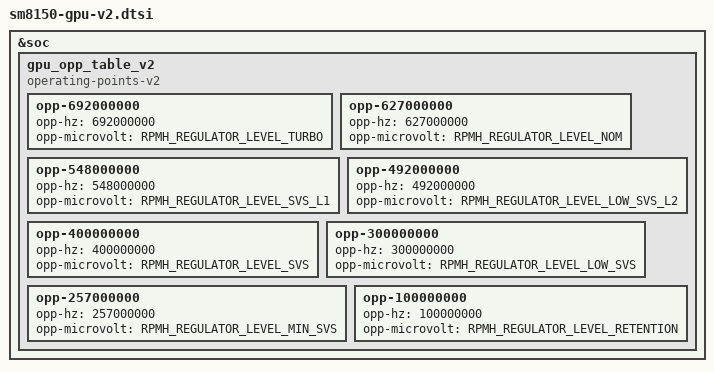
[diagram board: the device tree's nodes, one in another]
/* Copyright (c) 2018-2019, The Linux Foundation. All rights reserved.
 *
 * This program is free software; you can redistribute it and/or modify
 * it under the terms of the GNU General Public License version 2 and
 * only version 2 as published by the Free Software Foundation.
 *
 * This program is distributed in the hope that it will be useful,
 * but WITHOUT ANY WARRANTY; without even the implied warranty of
 * MERCHANTABILITY or FITNESS FOR A PARTICULAR PURPOSE.  See the
 * GNU General Public License for more details.
 */

&soc {
	gpu_opp_table_v2: gpu_opp_table_v2 {
		compatible = "operating-points-v2";

		opp-692000000 {
			opp-hz = /bits/ 64 <692000000>;
			opp-microvolt = <RPMH_REGULATOR_LEVEL_TURBO>;
		};

		opp-627000000 {
			opp-hz = /bits/ 64 <627000000>;
			opp-microvolt = <RPMH_REGULATOR_LEVEL_NOM>;
		};

		opp-548000000 {
			opp-hz = /bits/ 64 <548000000>;
			opp-microvolt = <RPMH_REGULATOR_LEVEL_SVS_L1>;
		};

		opp-492000000 {
			opp-hz = /bits/ 64 <492000000>;
			opp-microvolt = <RPMH_REGULATOR_LEVEL_LOW_SVS_L2>;
		};

		opp-400000000 {
			opp-hz = /bits/ 64 <400000000>;
			opp-microvolt = <RPMH_REGULATOR_LEVEL_SVS>;
		};

		opp-300000000 {
			opp-hz = /bits/ 64 <300000000>;
			opp-microvolt = <RPMH_REGULATOR_LEVEL_LOW_SVS>;
		};

		opp-257000000 {
			opp-hz = /bits/ 64 <257000000>;
			opp-microvolt = <RPMH_REGULATOR_LEVEL_MIN_SVS>;
		};

		opp-100000000 {
			opp-hz = /bits/ 64 <100000000>;
			opp-microvolt = <RPMH_REGULATOR_LEVEL_RETENTION>;
		};
	};
};
